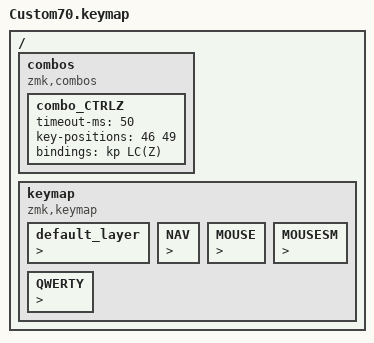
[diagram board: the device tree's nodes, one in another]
/*
 * Copyright (c) 2021 The ZMK Contributors
 *
 * SPDX-License-Identifier: MIT
 */
 
#include <behaviors.dtsi>
#include <dt-bindings/zmk/keys.h>
#include <dt-bindings/zmk/bt.h>
#include <dt-bindings/zmk/mouse.h>
#include <dt-bindings/zmk/outputs.h>

#define DEFAULT 0
#define NAV     1
#define MOUSE   2
#define MOUSESM 3
#define QWERTY  4

/ {
    combos {
        compatible = "zmk,combos";
        combo_CTRLZ {
            timeout-ms = <50>;
            key-positions = <46 49>;
            bindings = <&kp LC(Z)>;
        };
    };
};

/ {
    keymap {
        compatible = "zmk,keymap";

        default_layer {
//╭──────────┬──────────┬──────────┬──────────┬──────────┬──────────┬──────────┬──────────┬──────────┬──────────┬──────────┬──────────┬──────────┬──────────┬──────────────╮
    &kp ESC   &kp EQUAL    &kp N1     &kp N2     &kp N3     &kp N4     &kp N5     &kp N6     &kp N7     &kp N8     &kp N9     &kp N0    &kp SEMI  &kp PSCRN   &kp K_VOL_UP
//├──────────┴────┬──────┴───┬───────┴──┬─────┴────┬─────┴────┬─────┴────┬─────┴────┬─────┴────┬─────┴────┬─────┴────┬─────┴────┬─────┴────┬─────┴──────────┼──────────────┤
    &kp TAB         &kp SQT   &kp COMMA   &kp DOT     &kp P      &kp Y     &kp FSLH    & kp F     &kp G      &kp C      &kp R      &kp L       &kp MINUS      &kp C_VOL_DN
//├─────────────┲━┷━━━━━━━━┳━┷━━━━━━━━┳━┷━━━━━━━━┳━┷━━━━━━━━┱─┴────────┬─┴──────────┴───┬──────┴───┲━━━━━━┷━━━┳━━━━━━┷━━━┳━━━━━━┷━━━┳━━━━━━━━┷━┱──────────┬─┴──────────────┤
    &kp BSPC       &kp A      &kp O       &kp E     &kp U      &kp I       &kp BSLH         &kp D     &kp H      &kp T      &kp N      &kp S    &kp RSHIFT    &kp KP_ENTER
//├──────────┬──┺━━━━━━━━┯━━┻━━━━━━┯━━┻━━━━━━━┯━━┻━━━━━━━┯━━┹───────┬──┴───────┬────────┴─┬────────┺━┯━━━━━━━━┻━┯━━━━━━━━┻━┯━━━━━━━━┻━┯━━━━━━━━┹─┬────────┴─┬──────────────┤
    &kp LSHIFT  &kp LSHIFT   &kp Q      &kp J     &kp K       &kp X     &kp LBKT   &kp RBKT   &kp B       &kp M     &kp W      &kp V      &kp Z      &kp UP     &bt BT_NXT
//├──────────┴──┬───────┴─┬────────┴────┬─────┴──────────┴──────────┴───┬──────┴───────┬──┴──────────┴───────┬──┴───────┬──┴──────────┼──────────┼──────────┼──────────────┤
    &kp LCTRL    &kp LGUI    &kp LALT              &kp SPACE                &tog 2        &mo 1                  &kp DEL    &kp RCTRL   &kp LEFT   &kp DOWN    &kp RIGHT
//╰─────────────┴─────────┴─────────────┴───────────────────────────────┴──────────────┴─────────────────────┴──────────┴─────────────┴──────────┴──────────┴──────────────╯
            >;
        };

        NAV {
//╭──────────┬──────────┬──────────┬──────────┬──────────┬──────────┬──────────┬──────────┬──────────┬──────────┬──────────┬──────────┬──────────┬──────────┬──────────────╮
    &TILDE       &GRAVE    &kp F1     &kp F2     &kp F3     &kp F4     &kp F5     &kp F6     &kp F7     &kp F8     &kp F9     &kp F10    &kp F11   &kp F12      &tog 4
//├──────────┴────┬──────┴───┬───────┴──┬─────┴────┬─────┴────┬─────┴────┬─────┴────┬─────┴────┬─────┴────┬─────┴────┬─────┴────┬─────┴────┬─────┴──────────┼──────────────┤
    &trans         &trans     &trans     &kp UP     &kp K_APP   &kp ESC    &trans    &trans     &kp N7      &kp N8    &kp N9      &trans       &trans          &trans    
//├─────────────┲━┷━━━━━━━━┳━┷━━━━━━━━┳━┷━━━━━━━━┳━┷━━━━━━━━┱─┴────────┬─┴──────────┴───┬──────┴───┲━━━━━━┷━━━┳━━━━━━┷━━━┳━━━━━━┷━━━┳━━━━━━━━┷━┱──────────┬─┴──────────────┤
    &trans       &kp LEFT    &kp LEFT   &kp DOWN   &kp RIGHT  &kp ENTER       &trans        &trans     &kp N4     &kp N5      &kp N6    &trans   &trans     &trans      
//├──────────┬──┺━━━━━━━━┯━━┻━━━━━━┯━━┻━━━━━━━┯━━┻━━━━━━━┯━━┹───────┬──┴───────┬────────┴─┬────────┺━┯━━━━━━━━┻━┯━━━━━━━━┻━┯━━━━━━━━┻━┯━━━━━━━━┹─┬────────┴─┬──────────────┤
    &none      &trans      &trans      &trans      &trans     &trans   &trans     &trans     &kp N0      &kp N1     &kp N2      &kp N3      &trans   &trans    &trans    
//├──────────┴──┬───────┴─┬────────┴────┬─────┴──────────┴──────────┴───┬──────┴───────┬──┴──────────┴───────┬──┴───────┬──┴──────────┼──────────┼──────────┼──────────────┤
    &trans        &trans      &tog 1        &trans                          &kp LSHIFT          &trans           &trans      &tog 1       &trans    &trans      &trans 
//╰─────────────┴─────────┴─────────────┴───────────────────────────────┴──────────────┴─────────────────────┴──────────┴─────────────┴──────────┴──────────┴──────────────╯
        
            >;
        };

        MOUSE {
//╭──────────┬──────────┬──────────┬──────────┬──────────┬──────────┬──────────┬──────────┬──────────┬──────────┬──────────┬──────────┬──────────┬──────────┬──────────────╮
     &trans    &tran  &bt BT_SEL 0  &bt BT_SEL 1 &bt BT_SEL 2 &bt BT_SEL 3 &trans  &trans    &trans     &trans     &trans      &trans    &trans     &trans    &bt BT_CLR
//├──────────┴────┬──────┴───┬───────┴──┬─────┴────┬─────┴────┬─────┴────┬─────┴────┬─────┴────┬─────┴────┬─────┴────┬─────┴────┬─────┴────┬─────┴──────────┼──────────────┤
    &trans          &trans     &trans   &kp MOVE(0,-600) &kp RCLK  &kp SCROLL_UP &trans    &trans     &kp AMPS   &kp ASTRK    &kp LPAR   &kp RPAR      &trans   &out OUT_TOG
//├─────────────┲━┷━━━━━━━━┳━┷━━━━━━━━┳━┷━━━━━━━━┳━┷━━━━━━━━┱─┴────────┬─┴──────────┴───┬──────┴───┲━━━━━━┷━━━┳━━━━━━┷━━━┳━━━━━━┷━━━┳━━━━━━━━┷━┱──────────┬─┴──────────────┤
  &trans &kp MOVE(-600,0) &kp MOVE(-600,0) &kp MOVE(0,600) &kp MOVE(600,0) &kp SCROLL_DOWN &trans &trans &kp DOLLAR  &kp PRCNT &kp CARE  &trans   &trans        &trans
//├──────────┬──┺━━━━━━━━┯━━┻━━━━━━┯━━┻━━━━━━━┯━━┻━━━━━━━┯━━┹───────┬──┴───────┬────────┴─┬────────┺━┯━━━━━━━━┻━┯━━━━━━━━┻━┯━━━━━━━━┻━┯━━━━━━━━┹─┬────────┴─┬──────────────┤
    &none      &trans      &trans      &trans      &trans  &kp MCLK   &trans     &trans     &kp RPAR  &kp EXCL  &kp AT      &kp HASH    &trans    &trans        &bootloader
//├──────────┴──┬───────┴─┬────────┴────┬─────┴──────────┴──────────┴───┬──────┴───────┬──┴──────────┴───────┬──┴───────┬──┴──────────┼──────────┼──────────┼──────────────┤
    &trans        &trans      &mo 3        &kp LCLK                       &tog 2          &mo 1                &trans      &tog 2       &trans    &trans     &trans 
//╰─────────────┴─────────┴─────────────┴───────────────────────────────┴──────────────┴─────────────────────┴──────────┴─────────────┴──────────┴──────────┴──────────────╯
   
               >;
        };
        
        MOUSESM {
//╭──────────┬──────────┬──────────┬──────────┬──────────┬──────────┬──────────┬──────────┬──────────┬──────────┬──────────┬──────────┬──────────┬──────────┬──────────────╮
     &trans    &trans      &trans     &trans      &trans    &trans     &trans     &trans     &trans     &trans     &trans      &trans    &trans     &trans     &trans
//├──────────┴────┬──────┴───┬───────┴──┬─────┴────┬─────┴────┬─────┴────┬─────┴────┬─────┴────┬─────┴────┬─────┴────┬─────┴────┬─────┴────┬─────┴──────────┼──────────────┤
    &trans          &trans     &trans   &kp MOVE(0,-200) &trans  &trans      &trans    &trans     &trans    &trans     &trans     &trans        &trans         &trans
//├─────────────┲━┷━━━━━━━━┳━┷━━━━━━━━┳━┷━━━━━━━━┳━┷━━━━━━━━┱─┴────────┬─┴──────────┴───┬──────┴───┲━━━━━━┷━━━┳━━━━━━┷━━━┳━━━━━━┷━━━┳━━━━━━━━┷━┱──────────┬─┴──────────────┤
  &trans &kp MOVE(-200,0) &kp MOVE(-200,0) &kp MOVE(0,200) &kp MOVE(200,0) &trans  &trans   &trans     &trans   &trans     &trans    &trans      &trans        &trans
//├──────────┬──┺━━━━━━━━┯━━┻━━━━━━┯━━┻━━━━━━━┯━━┻━━━━━━━┯━━┹───────┬──┴───────┬────────┴─┬────────┺━┯━━━━━━━━┻━┯━━━━━━━━┻━┯━━━━━━━━┻━┯━━━━━━━━┹─┬────────┴─┬──────────────┤
    &none      &trans      &trans      &trans      &trans  &trans   &trans     &trans     &trans     &trans     &trans      &trans     &trans    &trans     &trans
//├──────────┴──┬───────┴─┬────────┴────┬─────┴──────────┴──────────┴───┬──────┴───────┬──┴──────────┴───────┬──┴───────┬──┴──────────┼──────────┼──────────┼──────────────┤
    &trans        &trans      &trans         &trans                         &trans         &trans                &trans      &tog 3       &trans    &trans     &trans 
//╰─────────────┴─────────┴─────────────┴───────────────────────────────┴──────────────┴─────────────────────┴──────────┴─────────────┴──────────┴──────────┴──────────────╯
        
            >;
        };
        
        QWERTY{
//╭──────────┬──────────┬──────────┬──────────┬──────────┬──────────┬──────────┬──────────┬──────────┬──────────┬──────────┬──────────┬──────────┬──────────┬──────────────╮
    &trans    &trans      &trans     &trans      &trans    &trans     &trans     &trans     &trans     &trans     &trans       &trans    &trans    &trans     &trans
//├──────────┴────┬──────┴───┬───────┴──┬─────┴────┬─────┴────┬─────┴────┬─────┴────┬─────┴────┬─────┴────┬─────┴────┬─────┴────┬─────┴────┬─────┴──────────┼──────────────┤
    &trans          &kp Q      &kp W      &kp E      &kp R     &kp T     &trans        & kp Y     &kp U      &kp I     &kp O      &kp P       &kp MINUS       &trans
//├─────────────┲━┷━━━━━━━━┳━┷━━━━━━━━┳━┷━━━━━━━━┳━┷━━━━━━━━┱─┴────────┬─┴──────────┴───┬──────┴───┲━━━━━━┷━━━┳━━━━━━┷━━━┳━━━━━━┷━━━┳━━━━━━━━┷━┱──────────┬─┴──────────────┤
    &trans          &kp A      &kp O       &kp E     &kp U      &kp I       &trans         &kp H     &kp J      &kp K      &kp L      &kp SEMI     &trans     &trans
//├──────────┬──┺━━━━━━━━┯━━┻━━━━━━┯━━┻━━━━━━━┯━━┻━━━━━━━┯━━┹───────┬──┴───────┬────────┴─┬────────┺━┯━━━━━━━━┻━┯━━━━━━━━┻━┯━━━━━━━━┻━┯━━━━━━━━┹─┬────────┴─┬──────────────┤
    &kp LSHIFT   &kp Z     &kp X      &kp C     &kp V       &kp B     &trans     &trans   &kp N       &kp M       &kp COMMA   &kp DOT   &kp FSLH   &trans     &trans
//├──────────┴──┬───────┴─┬────────┴────┬─────┴──────────┴──────────┴───┬──────┴───────┬──┴──────────┴───────┬──┴───────┬──┴──────────┼──────────┼──────────┼──────────────┤
    &trans        &trans       &trans              &trans                  &kp LSHIFT          &trans           &trans       &tog 4      &trans   &trans     &trans
//╰─────────────┴─────────┴─────────────┴───────────────────────────────┴──────────────┴─────────────────────┴──────────┴─────────────┴──────────┴──────────┴──────────────╯
      
        
            >;
        };

      
    };
};
